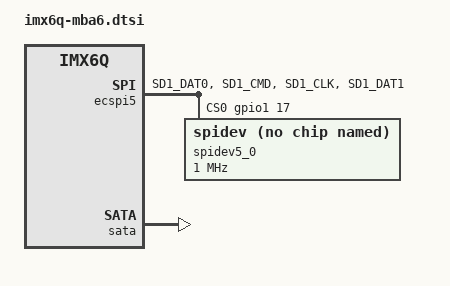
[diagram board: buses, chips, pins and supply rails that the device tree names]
/*
 * Copyright 2015 Markus Niebel TQ Systems GmbH
 *
 * The code contained herein is licensed under the GNU General Public
 * License. You may obtain a copy of the GNU General Public License
 * Version 2 or later at the following locations:
 *
 * http://www.opensource.org/licenses/gpl-license.html
 * http://www.gnu.org/copyleft/gpl.html
 */

&ecspi5 {
	pinctrl-names = "default";
	pinctrl-0 = <&pinctrl_ecspi5_mba6x>;
	fsl,spi-num-chipselects = <1>;
	cs-gpios = <&gpio1 17 0>;
	status = "okay";

	/* TODO: newer kernel does not spidev directly */
	spidev5_0: spidev5-0@0 {
		compatible = "spidev";
		spi-max-frequency = <1000000>;
		reg = <0>;
		status = "okay";
	};
};

&iomuxc {
	ecspi5 {
		pinctrl_ecspi5_mba6x: ecspi5grp-mba6x {
			fsl,pins = <
				/* HYS, SPEED = MED, 100k up, DSE = 011, SRE_FAST */
				MX6QDL_PAD_SD1_DAT0__ECSPI5_MISO 0x1b099
				MX6QDL_PAD_SD1_CMD__ECSPI5_MOSI 0xb099
				MX6QDL_PAD_SD1_CLK__ECSPI5_SCLK 0xb099
				MX6QDL_PAD_SD1_DAT1__GPIO1_IO17 0xb099 /* eCSPI5 SS0 */
			>;
		};
	};
};

&sata {
	status = "okay";
};
